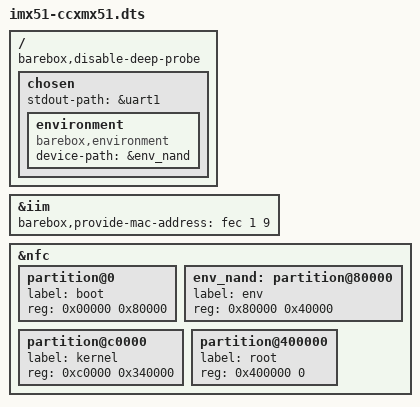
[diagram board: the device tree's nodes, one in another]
/* SPDX-License-Identifier: GPL-2.0+ */
/* Author: Alexander Shiyan <shc_work@mail.ru> */

#include <arm/nxp/imx/imx51-digi-connectcore-jsk.dts>

/ {
	barebox,disable-deep-probe;

	chosen {
		stdout-path = &uart1;

		environment {
			compatible = "barebox,environment";
			device-path = &env_nand;
		};
	};
};

&iim {
	barebox,provide-mac-address = <&fec 1 9>;
};

&nfc {
	partition@0 {
		label = "boot";
		reg = <0x00000 0x80000>;
	};

	env_nand: partition@80000 {
		label = "env";
		reg = <0x80000 0x40000>;
	};

	partition@c0000 {
		label = "kernel";
		reg = <0xc0000 0x340000>;
	};

	partition@400000 {
		label = "root";
		reg = <0x400000 0>;
	};
};
